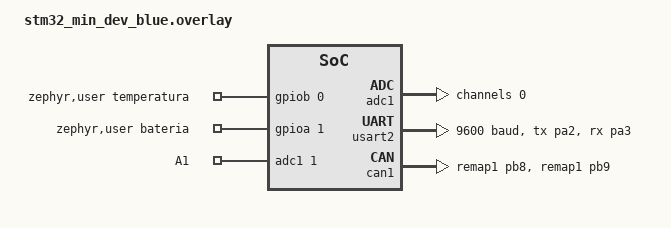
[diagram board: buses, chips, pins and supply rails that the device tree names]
/ {
    zephyr,user {
       temperatura_gpios = <&gpiob 0 GPIO_ACTIVE_HIGH>; // Não pode mudar
       io-channels = <&adc1 1>; // Canal 1 = Pino A1
       io-channel-names = "A1";
       bateria_gpios = <&gpioa 1 GPIO_ACTIVE_HIGH>; // Tensão da bateria 
    };

    // Usado para inicializar aliases de outros devices no código
    aliases {
        tpms = &usart2;
        mycan = &can1;
    };
};

&adc1 {
	#address-cells = <1>;
	#size-cells = <0>;

	channel@0 {
		reg = <0>;
		zephyr,gain = "ADC_GAIN_1";
		zephyr,reference = "ADC_REF_INTERNAL";
		zephyr,acquisition-time = <ADC_ACQ_TIME_DEFAULT>;
		zephyr,resolution = <12>;
	};
};

&usart2 {
    dmas = <&dma1 7 (STM32_DMA_PERIPH_TX | STM32_DMA_PRIORITY_HIGH)>,
           <&dma1 6 (STM32_DMA_PERIPH_RX | STM32_DMA_PRIORITY_HIGH)>;
    dma-names = "tx", "rx";

    pinctrl-0 = <&usart2_tx_pa2 &usart2_rx_pa3>;    //NOTE:
                                                    // TX: PA2
                                                    // RX: PA3
    pinctrl-names = "default";

    current-speed = <9600>;
    status = "okay";
};

&dma1 {
    status = "okay";
};

&can1 {
    status = "okay";
    pinctrl-0 = <&can_rx_remap1_pb8 &can_tx_remap1_pb9>;
    pinctrl-names= "default";
};

/* vim: set filetype=dts : */
